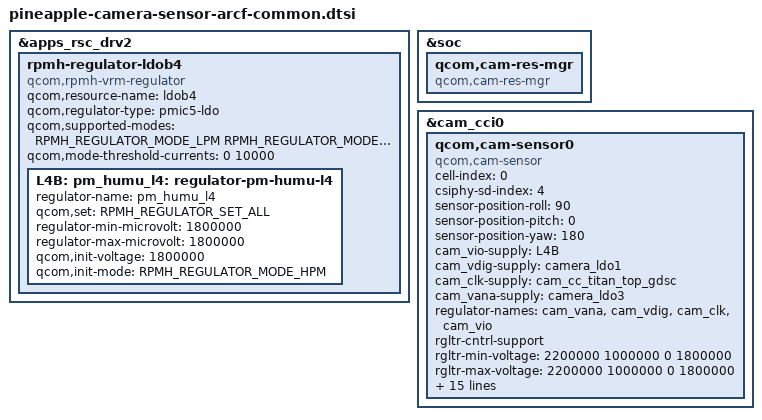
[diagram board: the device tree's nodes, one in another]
#include <dt-bindings/msm-camera.h>
#include <dt-bindings/regulator/qcom,rpmh-regulator-levels.h>

&apps_rsc_drv2 {
       rpmh-regulator-ldob4 {
               compatible = "qcom,rpmh-vrm-regulator";
               qcom,resource-name = "ldob4";
               qcom,regulator-type = "pmic5-ldo";
               qcom,supported-modes =
                       <RPMH_REGULATOR_MODE_LPM
                        RPMH_REGULATOR_MODE_HPM>;
               qcom,mode-threshold-currents = <0 10000>;

               L4B: pm_humu_l4: regulator-pm-humu-l4 {
                       regulator-name = "pm_humu_l4";
                       qcom,set = <RPMH_REGULATOR_SET_ALL>;
                       regulator-min-microvolt = <1800000>;
                       regulator-max-microvolt = <1800000>;
                       qcom,init-voltage = <1800000>;
                       qcom,init-mode = <RPMH_REGULATOR_MODE_HPM>;
               };
       };
};

&soc {
	qcom,cam-res-mgr {
		compatible = "qcom,cam-res-mgr";
		status = "ok";
	};
};

&cam_cci0 {

  qcom,cam-sensor0 {
  	cell-index = <0>;
	compatible = "qcom,cam-sensor";
	csiphy-sd-index = <4>;
	sensor-position-roll = <90>;
	sensor-position-pitch = <0>;
	sensor-position-yaw = <180>;
	cam_vio-supply = <&L4B>;
	cam_vdig-supply = <&camera_ldo1>;
	cam_clk-supply = <&cam_cc_titan_top_gdsc>;
	cam_vana-supply = <&camera_ldo3>;
	regulator-names = "cam_vana",
		"cam_vdig","cam_clk","cam_vio";
	rgltr-cntrl-support;
	rgltr-min-voltage = <2200000 1000000 0 1800000>;
	rgltr-max-voltage = <2200000 1000000 0 1800000>;
	rgltr-load-current = <101000 787000 0 1000>;
	gpio-no-mux = <0>;

	pinctrl-names = "cam_default", "cam_suspend";
	pinctrl-0 = <&cam_sensor_mclk1_active
		&cam_sensor_active_rst2>;
	pinctrl-1 = <&cam_sensor_mclk1_suspend
		&cam_sensor_suspend_rst2>;
	gpios = <&tlmm 101 0>,
		<&tlmm 3 0>;
	gpio-reset = <1>;
	gpio-req-tbl-num = <0 1>;
	gpio-req-tbl-flags = <1 0>;
	gpio-req-tbl-label = "CAMIF_MCLK1",
			"CAM_RESET2";
	cci-master = <CCI_MASTER_0>;
	clocks = <&camcc CAM_CC_MCLK1_CLK>;
	clock-names = "cam_clk";
	clock-cntl-level = "nominal";
	clock-rates = <24000000>;
	status = "ok";
	};
};
